# D1H.pdf register map
Vendor: Allwinner; Series: D1H.pdf; File version: 0.1
CPU: XuanTie C906 RISC-V CPU 0, little endian, MPU, FPU, double-precision FPU, 0 interrupt priority bits
Registers are 32-bit, read-write, reset 0x0 unless marked. A register's access mark holds for its fields unless they carry their own. Offsets are from the block's base; [hi:lo] are bit positions; {n}, {i} and the like mark numbered series; 'fields as' and 'values as' point back to an identical list; <NAME> marks a mode.

## SPI_DBI
Base 0x04026000
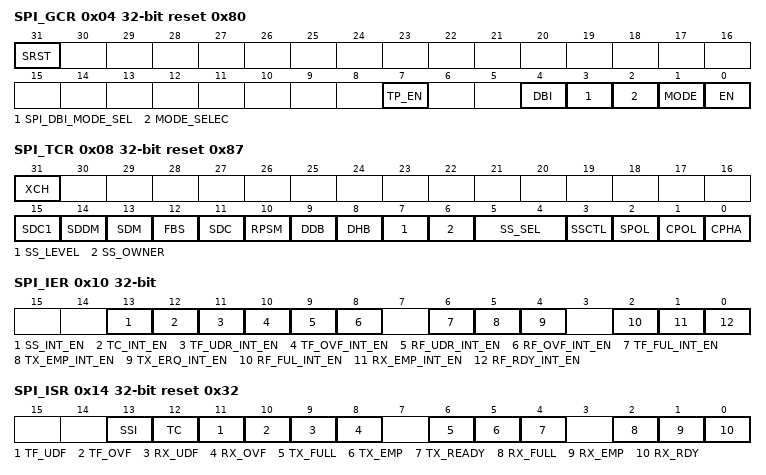
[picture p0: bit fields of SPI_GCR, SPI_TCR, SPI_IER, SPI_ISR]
0x04 SPI_GCR reset 0x80 — SPI Global Control Register
  [31] SRST — Soft reset Writing ‘1’ to this bit will clear the SPI controller, and auto clear to ‘0’ when reset operation completes. Writing ‘0’ to this bit has no effect.
  [7] TP_EN — Transmit Pause Enable In master mode, it is used to control transmit state machine to stop smart burst sending when RX FIFO is full. 0: Normal operation, ignore RXFIFO status 1: Stop transmit data when RXFIFO full Cannot be written when XCH=1.
    0=Normal operation, ignore RXFIFO status; 1=Stop transmit data when RXFIFO full Cannot be written when XCH=1
  [4] DBI — EN DBI Module Enable Control 0: Disable 1: Enable
    0=Disable; 1=Enable
  [3] SPI_DBI_MODE_SEL — DBI Working Mode Select 0: SPI MODE 1: DBI MODE
    0=SPI (SPI MODE); 1=DBI (DBI MODE)
  [2] MODE_SELEC — Sample Timing Mode Select 0: Old mode of Sample Timing 1: New mode of Sample Timing Cannot be written when XCH=1.
    0=Old mode of Sample Timing; 1=New mode of Sample Timing Cannot be written when XCH=1
  [1] MODE — SPI Function Mode Select 0: Slave mode 1: Master mode Cannot be written when XCH=1.
    0=Slave_mode; 1=Master mode Cannot be written when XCH=1
  [0] EN — SPI Module Enable Control 0: Disable 1: Enable After transforming from bit_mode to byte_mode, it must enable the SPI module again.
    0=Disable; 1=Enable After transforming from bit_mode to byte_mode, it must enable the SPI module again
0x08 SPI_TCR reset 0x87 — SPI Transfer Control Register
  [31] XCH — Exchange Burst In master mode, it is used to start SPI burst 0: Idle 1: Initiates exchange. Writing “1” to this bit will start the SPI burst, and will auto-clear after finishing the bursts transfer specified by BC. Writing “1” to SRST will also clear this bit. Writing ‘0’ to this bit has no effect. Cannot be written when XCH=1.
    0=Idle; 1=Initiates exchange. Writing “1” to this bit will start the SPI burst, and will auto-clear after finishing the bursts transfer specified by BC. Writing “1” to SRST will also clear this bit. Writing ‘0’ to this bit has no effect. Cannot be written when XCH=1.
  [15] SDC1 — Master Sample Data Control register1 Set this bit to ‘1’ to make the internal read sample point with a delay of half-cycle of SPI_CLK. It is used in high speed read operation to reduce the error caused by the time delay of SPI_CLK between master and slave. 0: Normal operation, do not delay the internal read sample point 1: Delay the internal read sample point Cannot be written when XCH=1.
    0=Normal operation, do not delay the internal read sample point; 1=Delay the internal read sample point Cannot be written when XCH=1
  [14] SDDM — Sending Data Delay Mode 0: Normal sending 1: Delay sending Set the bit to "1" to make the data that should be sent with a delay of half-cycle of SPI_CLK in dual IO mode for SPI mode 0. Cannot be written when XCH=1.
    0=Normal sending; 1=Delay sending Set the bit to "1" to make the data that should be sent with a delay of half-cycle of SPI_CLK in dual IO mode for SPI mode 0. Cannot be written when XCH=1.
  [13] SDM — Master Sample Data Mode 0: Delay sample mode 1: Normal sample mode In normal sample mode, the SPI master samples the data at the correct edge for each SPI mode; In delay sample mode, the SPI master samples data at the edge that is half cycle delayed by the correct edge defined in respective SPI mode. Cannot be written when XCH=1.
    0=Delay sample mode; 1=Normal sample mode In normal sample mode, the SPI master samples the data at the correct edge for each SPI mode; In delay sample mode, the SPI master samples data at the edge that is half cycle delayed by the correct edge defined in respective SPI mode. Cannot be written when XCH=1.
  [12] FBS — First Transmit Bit Select 0: MSB first. The upper bits are transmitted first. 1: LSB first. The lower bits are transmitted first. Cannot be written when XCH=1.
    0=MSB (MSB first. The upper bits are transmitted first.); 1=LSB (LSB first. The lower bits are transmitted first. Cannot be written when XCH=1.)
  [11] SDC — Master Sample Data Control Set this bit to ‘1’ to make the internal read sample point with a delay of half-cycle of SPI_CLK. It is used in high speed read operation to reduce the error caused by the time delay of SPI_CLK between master and slave. 0: Normal operation, do not delay the internal read sample point 1: Delay the internal read sample point Cannot be written when XCH=1.
    values as SDC1
  [10] RPSM — Rapids Mode Select Select rapid mode for high speed write. 0: Normal write mode 1: Rapid write mode Cannot be written when XCH=1.
    0=Normal write mode; 1=Rapid write mode Cannot be written when XCH=1
  [9] DDB — Dummy Burst Type 0: The bit value of dummy SPI burst is zero 1: The bit value of dummy SPI burst is one Cannot be written when XCH=1.
    0=zero (The bit value of dummy SPI burst is zero); 1=one (The bit value of dummy SPI burst is one Cannot be written when XCH=1.)
  [8] DHB — Discard Hash Burst In master mode, it controls whether discarding unused SPI bursts 0: Receiving all SPI bursts in the BC period 1: Discard unused SPI bursts, only fetching the SPI bursts during the dummy burst period. The burst number is specified by TC. Cannot be written when XCH=1.
    0=Receiving all SPI bursts in the BC period; 1=Discard unused SPI bursts, only fetching the SPI bursts during the dummy burst period. The burst number is specified by TC. Cannot be written when XCH=1.
  [7] SS_LEVEL — SPI Chip Select Level When control SS signal manually (SS_OWNER (SPI_TCR[6])==1), set this bit to ‘1’ or ‘0’ to control the level of SS signal. 0: Set SS to low 1: Set SS to high Cannot be written when XCH=1.
    0=Set_SS_to_low; 1=Set SS to high Cannot be written when XCH=1
  [6] SS_OWNER — SS Output Owner Select Usually, the controller sends the SS signal automatically with data together. When this bit is set to 1, the software must manually write SS_LEVEL (SPI_TCR[7]) to 1 or 0 to control the level of the SS signal. 0: SPI controller 1: Software Cannot be written when XCH=1.
    0=SPI (SPI controller); 1=Software Cannot be written when XCH=1
  [5:4] SS_SEL — SPI Chip Select Select one of four external SPI Master/Slave Devices 00: SPI_SS0 will be asserted 01: SPI_SS1 will be asserted 10: SPI_SS2 will be asserted 11: SPI_SS3 will be asserted Cannot be written when XCH=1.
    0=SPI_SS0 (SPI_SS0 will be asserted); 1=SPI_SS1 (SPI_SS1 will be asserted); 2=SPI_SS2 (SPI_SS2 will be asserted); 3=SPI_SS3 (SPI_SS3 will be asserted Cannot be written when XCH=1.)
  [3] SSCTL — In master mode, this bit selects the output waveform for the SPI_SSx signal. Only valid when SS_OWNER (SPI_TCR[6])= 0. 0: SPI_SSx remains asserted between SPI bursts 1: Negate SPI_SSx between SPI bursts Cannot be written when XCH=1.
    0=SPI_SSx remains asserted between SPI bursts; 1=Negate SPI_SSx between SPI bursts Cannot be written when XCH=1
  [2] SPOL — SPI Chip Select Signal Polarity Control 0: Active high polarity (0 = Idle) 1: Active low polarity (1 = Idle) Cannot be written when XCH=1.
    0=Active high polarity (0 = Idle); 1=Active low polarity (1 = Idle) Cannot be written when XCH=1
  [1] CPOL — SPI Clock Polarity Control 0: Active high polarity (0 = Idle) 1: Active low polarity (1 = Idle) Cannot be written when XCH=1.
    values as SPOL
  [0] CPHA — SPI Clock/Data Phase Control 0: Phase 0 (Leading edge for sample data) 1: Phase 1 (Leading edge for setup data) Cannot be written when XCH=1.
    0=Phase 0 (Leading edge for sample data); 1=Phase 1 (Leading edge for setup data) Cannot be written when XCH=1
0x10 SPI_IER — SPI Interrupt Control Register
  [all] fields
    0=Disable; 1=Enable
  [13] SS_INT_EN — SSI Interrupt Enable Chip select signal (SSx) from the valid state to the invalid state 0: Disable 1: Enable
  [12] TC_INT_EN — Transfer Completed Interrupt Enable 0: Disable 1: Enable
  [11] TF_UDR_INT_EN — TXFIFO Underrun Interrupt Enable 0: Disable 1: Enable
  [10] TF_OVF_INT_EN — TX FIFO Overflow Interrupt Enable 0: Disable 1: Enable
  [9] RF_UDR_INT_EN — RXFIFO Underrun Interrupt Enable 0: Disable 1: Enable
  [8] RF_OVF_INT_EN — RX FIFO Overflow Interrupt Enable 0: Disable 1: Enable
  [6] TF_FUL_INT_EN — TX FIFO Full Interrupt Enable 0: Disable 1: Enable
  [5] TX_EMP_INT_EN — TX FIFO Empty Interrupt Enable 0: Disable 1: Enable
  [4] TX_ERQ_INT_EN — TX FIFO Empty Request Interrupt Enable 0: Disable 1: Enable
  [2] RF_FUL_INT_EN — RX FIFO Full Interrupt Enable 0: Disable 1: Enable
  [1] RX_EMP_INT_EN — RX FIFO Empty Interrupt Enable 0: Disable 1: Enable
  [0] RF_RDY_INT_EN — RX FIFO Ready Request Interrupt Enable 0: Disable 1: Enable
0x14 SPI_ISR reset 0x32 — SPI Interrupt Status Register
  [13] SSI write-1-clears — SS Invalid Interrupt When SSI is 1, it indicates that SS has changed from the valid state to the invalid state. Writing 1 to this bit clears it.
  [12] TC write-1-clears — Transfer Completed In master mode, it indicates that all bursts specified by BC have been exchanged. In other conditions, when set, this bit indicates that all the data in TXFIFO has been loaded in the Shift register, and the Shift register has shifted out all the bits. Writing 1 to this bit clears it. 0: Busy 1: Transfer completed
    0=Busy; 1=Transfer completed
  [11] TF_UDF write-1-clears — TXFIFO Underrun This bit is set when the TXFIFO is underrun. Writing 1 to this bit clears it. 0: TXFIFO is not underrun 1: TXFIFO is underrun
    0=not_underrun (TXFIFO is not underrun); 1=underrun (TXFIFO is underrun)
  [10] TF_OVF write-1-clears — TXFIFO Overflow This bit is set when the TXFIFO is overflowed. Writing 1 to this bit clears it. 0: TXFIFO is not overflowed 1: TXFIFO is overflowed
    0=not_overflowed (TXFIFO is not overflowed); 1=overflowed (TXFIFO is overflowed)
  [9] RX_UDF write-1-clears — RXFIFO Underrun When set, this bit indicates that RXFIFO is underrun. Writing 1 to this bit clears it. 0: RXFIFO is not underrun 1: RXFIFO is underrun
    0=not_underrun (RXFIFO is not underrun); 1=underrun (RXFIFO is underrun)
  [8] RX_OVF write-1-clears — RXFIFO Overflow When set, this bit indicates that RXFIFO is overflowed. Writing 1 to this bit clears it. 0: RXFIFO is not overflowed 1: RXFIFO is overflowed
    0=not_overflowed (RXFIFO is not overflowed); 1=overflowed (RXFIFO is overflowed)
  [6] TX_FULL write-1-clears — TXFIFO Full This bit is set when the TXFIFO is full. Writing 1 to this bit clears it. 0: TXFIFO is not Full 1: TXFIFO is Full
    0=not_Full (TXFIFO is not Full); 1=Full (TXFIFO is Full)
  [5] TX_EMP write-1-clears — TXFIFO Empty This bit is set when the TXFIFO is empty. Writing 1 to this bit clears it. 0: TXFIFO contains one or more words. 1: TXFIFO is empty
    0=TXFIFO contains one or more words; 1=empty (TXFIFO is empty)
  [4] TX_READY write-1-clears — TXFIFO Ready 0: TX_WL > TX_TRIG_LEVEL 1: TX_WL <= TX_TRIG_LEVEL This bit will be immediately set to 1 if TX_WL <= TX_TRIG_LEVEL. Writing “1” to this bit clears it. The TX_WL is the water level of TXFIFO.
    0=TX_WL__gt_ (TX_WL > TX_TRIG_LEVEL); 1=TX_WL__lt__equals_ (TX_WL <= TX_TRIG_LEVEL This bit will be immediately set to 1 if TX_WL <= TX_TRIG_LEVEL. Writing “1” to this bit clears it. The TX_WL is the water level of TXFIFO.)
  [2] RX_FULL write-1-clears — RXFIFO Full This bit is set when the RXFIFO is full. Writing 1 to this bit clears it. 0: Not Full 1: Full
    0=Not_Full; 1=Full
  [1] RX_EMP write-1-clears — RXFIFO Empty This bit is set when the RXFIFO is empty. Writing 1 to this bit clears it. 0: Not empty 1: empty
    0=Not_empty; 1=empty
  [0] RX_RDY write-1-clears — RXFIFO Ready 0: RX_WL < RX_TRIG_LEVEL 1: RX_WL >= RX_TRIG_LEVEL This bit will be immediately set to 1 if RX_WL >= RX_TRIG_LEVEL. Writing “1” to this bit clears it. The RX_WL is the water level of RXFIFO.
    0=RX_WL__lt_ (RX_WL < RX_TRIG_LEVEL); 1=RX_WL__gt__equals_ (RX_WL >= RX_TRIG_LEVEL This bit will be immediately set to 1 if RX_WL >= RX_TRIG_LEVEL. Writing “1” to this bit clears it. The RX_WL is the water level of RXFIFO.)
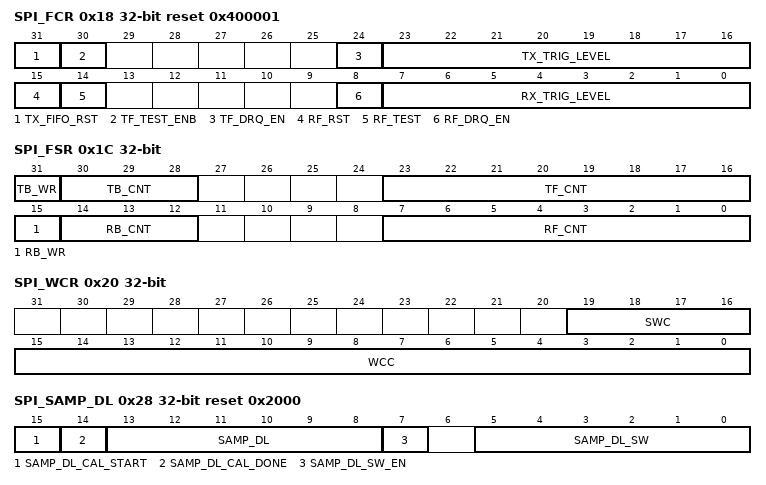
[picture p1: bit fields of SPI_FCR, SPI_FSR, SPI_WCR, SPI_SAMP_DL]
0x18 SPI_FCR reset 0x400001 — SPI FIFO Control Register
  [31] TX_FIFO_RST — TX FIFO Reset Writing ‘1’ to this bit will reset the control portion of the TXFIFO and auto clear to ‘0’ when completing the reset operation, writing ‘0’ to this bit has no effect.
  [30] TF_TEST_ENB — TX Test Mode Enable 0: Disable 1: Enable In normal mode, the TXFIFO can only be read by the SPI controller, writing ‘1’ to this bit will switch the read and write function of TXFIFO to AHB bus. This bit is used to test the TXFIFO, do not set in normal operation, and do not set RF_TEST and TF_TEST at the same time.
    0=Disable; 1=Enable In normal mode, the TXFIFO can only be read by the SPI controller, writing ‘1’ to this bit will switch the read and write function of TXFIFO to AHB bus. This bit is used to test the TXFIFO, do not set in normal operation, and do not set RF_TEST and TF_TEST at the same time.
  [24] TF_DRQ_EN — TX FIFO DMA Request Enable 0: Disable 1: Enable
    0=Disable; 1=Enable
  [23:16] TX_TRIG_LEVEL — TX FIFO Empty Request Trigger Level
  [15] RF_RST — RXFIFO Reset Writing ‘1’ to this bit will reset the control portion of the receiver FIFO, and auto clear to ‘0’ when completing the reset operation, writing ‘0’ to this bit has no effect.
  [14] RF_TEST — RX Test Mode Enable 0: Disable 1: Enable In normal mode, the RXFIFO can only be written by the SPI controller, writing ‘1’ to this bit will switch the read and write function of RXFIFO to AHB bus. This bit is used to test the RXFIFO, do not set in normal operation, and do not set RF_TEST and TF_TEST at the same time.
    0=Disable; 1=Enable In normal mode, the RXFIFO can only be written by the SPI controller, writing ‘1’ to this bit will switch the read and write function of RXFIFO to AHB bus. This bit is used to test the RXFIFO, do not set in normal operation, and do not set RF_TEST and TF_TEST at the same time.
  [8] RF_DRQ_EN — RXFIFO DMA Request Enable 0: Disable 1: Enable
    0=Disable; 1=Enable
  [7:0] RX_TRIG_LEVEL — RXFIFO Ready Request Trigger Level
0x1C SPI_FSR — SPI FIFO Status Register
  [31] TB_WR ro — TXFIFO Write Buffer Write Enable
  [30:28] TB_CNT ro — TXFIFO Write Buffer Counter These bits indicate the number of words in TXFIFO Write Buffer
  [23:16] TF_CNT ro — TXFIFO Counter These bits indicate the number of words in TXFIFO 0: 0 byte in TXFIFO 1: 1 byte in TXFIFO … 64: 64 bytes in TXFIFO other: Reserved
    64=64 bytes in TXFIFO other: Reserved
  [15] RB_WR ro — RXFIFO Read Buffer Write Enable
  [14:12] RB_CNT ro — RXFIFO Read Buffer Counter These bits indicate the number of words in RXFIFO Read Buffer
  [7:0] RF_CNT ro — RXFIFO Counter These bits indicate the number of words in RXFIFO 0: 0 byte in RXFIFO 1: 1 byte in RXFIFO … 64: 64 bytes in RXFIFO other: Reserved
    64=64 bytes in RXFIFO other: Reserved
0x20 SPI_WCR — SPI Wait Clock Register
  [19:16] SWC — Dual mode direction switch wait clock counter (for master mode only). These bits control the number of wait states to be inserted before starting dual data transfer in dual SPI mode. The SPI module counts SPI_SCLK by SWC for delaying the next word data transfer. 0: No wait states inserted n: n SPI_SCLK wait states inserted Cannot be written when XCH=1.
  [15:0] WCC — Wait Clock Counter (In master mode) These bits control the number of wait states to be inserted in data transfers. The SPI module counts SPI_SCLK by WCC for delaying the next word data transfer. 0: No wait states inserted n: n SPI_SCLK wait states inserted Cannot be written when XCH=1.
0x28 SPI_SAMP_DL reset 0x2000 — SPI Sample Delay Control Register
  [15] SAMP_DL_CAL_START — Sample Delay Calibration Start When set, it indicates that start sample delay chain calibration. Cannot be written when XCH=1.
  [14] SAMP_DL_CAL_DONE ro — Sample Delay Calibration Done When set, it indicates that the sample delay chain calibration is done and the result of calibration is shown in SAMP_DL. Cannot be written when XCH=1.
  [13:8] SAMP_DL ro — Sample Delay It indicates the number of delay cells corresponding to the current card clock. The delay time generated by these delay cells is equal to the cycle of the card clock nearly. Generally, it is necessary to do drive delay calibration when the card clock is changed. This bit is valid only when SAMP_DL_CAL_DONE is set. Cannot be written when XCH=1.
  [7] SAMP_DL_SW_EN — Sample Delay Software Enable When set, it indicates that enable sample delay specified at SAMP_DL_SW Cannot be written when XCH=1.
  [5:0] SAMP_DL_SW — Sample Delay Software The relative delay between the clock line and command line, data lines. It can be determined according to the value of SAMP_DL, the cycle of the card clock, and the input timing requirement of the device. Cannot be written when XCH=1.
0x30 SPI_MBC — SPI Master Burst Counter Register
  [23:0] MBC — Master Burst Counter In master mode, this field specifies the total burst number which includes the TXD, RXD, and dummy burst. 0: 0 burst 1: 1 burst … N: N bursts Cannot be written when XCH=1.
0x34 SPI_MTC — SPI Master Transmit Counter Register
  [23:0] MWTC — Master Write Transmit Counter In master mode, this field specifies the burst number that should be sent to TXFIFO before automatically sending dummy bursts. For saving bus bandwidth, the dummy bursts (all zero bits or all one bits) are sent by SPI Controller automatically. 0: 0 burst 1: 1 burst … N: N bursts Cannot be written when XCH=1.
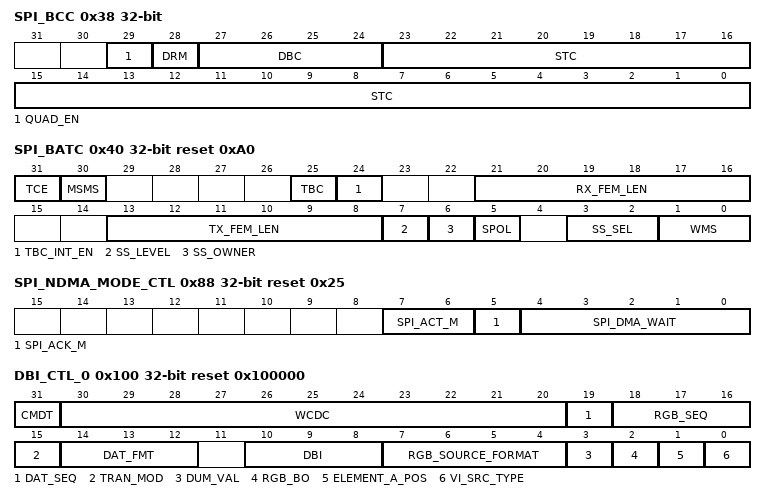
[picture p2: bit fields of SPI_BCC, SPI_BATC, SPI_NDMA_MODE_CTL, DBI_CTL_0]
0x38 SPI_BCC — SPI Master Burst Control Register
  [29] QUAD_EN — Quad_Mode_EN The Quad mode includes Quad-Input and Quad-Output. 0: Quad mode disable 1: Quad mode enable Cannot be written when XCH=1.
    0=disable (Quad mode disable); 1=enable (Quad mode enable Cannot be written when XCH=1.)
  [28] DRM — Master Dual Mode RX Enable It is only valid when Quad_Mode_EN=0. 0: RX uses the single-bit mode 1: RX uses the dual mode Cannot be written when XCH=1.
    0=RX uses the single-bit mode; 1=RX uses the dual mode Cannot be written when XCH=1
  [27:24] DBC — Master Dummy Burst Counter In master mode, this field specifies the burst number that should be sent before receiving in dual SPI mode. The data does not care by the device. 0: 0 burst 1: 1 burst … N: N bursts Cannot be written when XCH=1
  [23:0] STC — Master Single Mode Transmit Counter In master mode, this field specifies the burst number that should be sent in the single mode before automatically sending dummy bursts. This is the first transmit counter in all bursts. 0: 0 burst 1: 1 burst … N: N bursts Cannot be written when XCH=1
0x40 SPI_BATC reset 0xA0
  [31] TCE — Transfer Control Enable In master mode, it is used to start to transfer the serial bits frame, it is only valid when Work Mode Select==0x10/0x11. 0: Idle 1: Initiates transfer Writing “1” to this bit will start to transfer serial bits frame (the value comes from the SPI TX Bit Register or SPI RX Bit Register), and will auto-clear after the bursts transfer completely. Writing ‘0’ to this bit has no effect.
    0=Idle; 1=Initiates transfer Writing “1” to this bit will start to transfer serial bits frame (the value comes from the SPI TX Bit Register or SPI RX Bit Register), and will auto-clear after the bursts transfer completely. Writing ‘0’ to this bit has no effect.
  [30] MSMS — Master Sample Standard 0: Delay Sample Mode 1: Standard Sample Mode In Standard Sample Mode, the SPI master samples the data at the standard rising edge of SCLK for each SPI mode; In Delay Sample Mode, the SPI master samples data at the edge that is half cycle delayed by the standard rising edge of SCLK defined in respective SPI mode.
    0=Delay Sample Mode; 1=Standard Sample Mode In Standard Sample Mode, the SPI master samples the data at the standard rising edge of SCLK for each SPI mode; In Delay Sample Mode, the SPI master samples data at the edge that is half cycle delayed by the standard rising edge of SCLK defined in respective SPI mode
  [25] TBC write-1-clears — Transfer Bits Completed When set, this bit indicates that the last bit of the serial data frame in SPI TX Bit Register (or SPI RX Bit Register) has been transferred completely. Writing 1 to this bit clears it. 0: Busy 1: Transfer Completed It is only valid when Work Mode Select==0x10/0x11.
    0=Busy; 1=Transfer Completed It is only valid when Work Mode Select==0x10/0x11
  [24] TBC_INT_EN — Transfer Bits Completed Interrupt Enable 0: Disable 1: Enable It is only valid when Work Mode Select==0x10/0x11.
    0=Disable; 1=Enable It is only valid when Work Mode Select==0x10/0x11
  [21:16] RX_FEM_LEN — Configure the length of serial data frame (burst) of RX 000000: 0 bit 000001: 1 bit … 100000: 32 bits Other values: reserved It is only valid when Work Mode Select==0x10/0x11, and cannot be written when TCE (SPI_BATC[31])=1.
    0=_0_bit; 1=_1_bit; 32=32 bits Other values: reserved It is only valid when Work Mode Select==0x10/0x11, and cannot be written when TCE (SPI_BATC[31])=1
  [13:8] TX_FEM_LEN — Configure the length of serial data frame (burst) of TX 000000: 0 bit 000001: 1 bit … 100000: 32 bits Other values: reserved It is only valid when Work Mode Select==0x10/0x11, and cannot be written when TCE=1.
    0=_0_bit; 1=_1_bit; 32=32 bits Other values: reserved It is only valid when Work Mode Select==0x10/0x11, and cannot be written when TCE=1
  [7] SS_LEVEL — When control SS signal manually, set this bit to ‘1’ or ‘0’ to control the level of SS signal. 0: Set SS to low 1: Set SS to high It is only valid when Work Mode Select==0x10/0x11, and only work in Mode0, cannot be written when TCE=1.
    0=Set_SS_to_low; 1=Set SS to high It is only valid when Work Mode Select==0x10/0x11, and only work in Mode0, cannot be written when TCE=1
  [6] SS_OWNER — SS Output Owner Select Usually, the controller sends the SS signal automatically with data together. When this bit is set to 1, the software must manually write SS_LEVEL (SPI_BATC[7]) to 1 or 0 to control the level of the SS signal. 0: SPI controller 1: Software It is only valid when Work Mode Select==0x10/0x11, and only work in Mode0, cannot be written when TCE=1.
    0=SPI (SPI controller); 1=Software It is only valid when Work Mode Select==0x10/0x11, and only work in Mode0, cannot be written when TCE=1
  [5] SPOL — SPI Chip Select Signal Polarity Control 0: Active high polarity (0 = Idle) 1: Active low polarity (1 = Idle) It is only valid when Work Mode Select==0x10/0x11, and only work in Mode0, cannot be written when TCE=1.
    0=Active high polarity (0 = Idle); 1=Active low polarity (1 = Idle) It is only valid when Work Mode Select==0x10/0x11, and only work in Mode0, cannot be written when TCE=1
  [3:2] SS_SEL — SPI Chip Select Select one of four external SPI Master/Slave Devices 00: SPI_SS0 will be asserted 01: SPI_SS1 will be asserted 10: SPI_SS2 will be asserted 11: SPI_SS3 will be asserted It is only valid when Work Mode Select==0x10/0x11, and only work in Mode0, cannot be written when TCE=1.
    0=SPI_SS0 (SPI_SS0 will be asserted); 1=SPI_SS1 (SPI_SS1 will be asserted); 2=SPI_SS2 (SPI_SS2 will be asserted); 3=SPI_SS3 (SPI_SS3 will be asserted It is only valid when Work Mode Select==0x10/0x11, and only work in Mode0, cannot be written when TCE=1.)
  [1:0] WMS — Work Mode Select 00: Data frame is byte aligned in standard SPI, dual-output/dual input SPI, dual IO SPI, and quad-output/quad-input SPI 01: Reserved 10: Data frame is bit aligned in 3-wire SPI 11: Data frame is bit aligned in standard SPI
    0=byte_aligned_in_standard (Data frame is byte aligned in standard SPI, dual-output/dual input SPI, dual IO SPI, and quad-output/quad-input SPI); 2=bit_aligned_in_3_wire (Data frame is bit aligned in 3-wire SPI); 3=bit_aligned_in_standard (Data frame is bit aligned in standard SPI)
0x44 SPI_BA_CCR — SPI Bit-Aligned Clock Configuration Register
  [7:0] CDR_N — Clock Divide Rate (Master Mode Only) The SPI_SCLK is determined according to the following equation: SPI_CLK = Source_CLK / (2*(CDR_N + 1)). This register is only valid when Work Mode Select==0x10/0x11.
0x48 SPI_TBR — SPI TX Bit Register
  [31:0] VTB — The Value of the Transmit Bits This register is used to store the value of the transmitted serial data frame. In the process of transmission, the LSB is transmitted first. This register is only valid when Work Mode Select==0x10/0x11.
0x4C SPI_RBR — SPI RX Bit Register
  [31:0] VRB — The Value of the Receive Bits This register is used to store the value of the received serial data frame. In the process of transmission, the LSB is transmitted first. This register is only valid when Work Mode Select==0x10/0x11.
0x88 SPI_NDMA_MODE_CTL reset 0x25 (reset mask 0x3F) — SPI Normal DMA Mode Control Register
  [7:6] SPI_ACT_M — SPI NDMA Active Mode 00: dma_active is low 01: dma_active is high 10: dma_active is controlled by dma_request (DRQ) 11: dma_active is controlled by controller
  [5] SPI_ACK_M — SPI NDMA Acknowledge Mode 0: active fall do not care ack 1: active fall must after detect ack is high
    0=active fall do not care ack; 1=active fall must after detect ack is high
  [4:0] SPI_DMA_WAIT — Delay Cycles The counts of hold cycles from DMA last signal high to dma_active high
0x100 DBI_CTL_0 reset 0x100000 — DBI Control Register 0
  [31] CMDT — Command Type 0: Write Command 1: Read Command
    0=Write Command; 1=Read Command
  [30:20] WCDC — Write Command Dummy Cycles Controls dummy cycles between two write commands Range 1~255 Default Condition: there is a dbi_clk cycle between each command or parameter.
  [19] DAT_SEQ — Output Data Sequence 0: MSB First 1: LSB First
    0=MSB (MSB First); 1=LSB (LSB First)
  [18:16] RGB_SEQ — Output RGB Sequence 000: RGB 001: RBG 010: GRB 011: GBR 100: BRG 101: BGR 110, 111: Reserved
    0=RGB; 1=RBG; 2=GRB; 3=GBR; 4=BRG; 5=BGR (BGR 110, 111: Reserved)
  [15] TRAN_MOD — Transmit Mode 0: Command/Parameter 1: Video
    0=Command_slash_Parameter (Command/Parameter); 1=Video
  [14:12] DAT_FMT — Output Data Format 000: RGB111 001: RGB444 010: RGB565 011: RGB666 100: RGB888 (only for 2 Data Lane Interface) 101~111: Reserved
    0=RGB111; 1=RGB444; 2=RGB565; 3=RGB666; 4=RGB888 (RGB888 (only for 2 Data Lane Interface) 101~111: Reserved)
  [10:8] DBI — Interface 000: 3 Line Interface I 001: 3 Line Interface II 010: 4 Line Interface I 011: 4 Line Interface II 100: 2 Data Lane Interface
    0=_3_Line_Interface_I; 1=_3_Line_Interface_II; 2=_4_Line_Interface_I; 3=_4_Line_Interface_II; 4=_2_Data_Lane_Interface
  [7:4] RGB_SOURCE_FORMAT — When video_source_type is RGB32 (DBI_CTL_0[bit0] = 0) 0000: RGB 0001: RBG 0010: GRB 0011: GBR 0100: BRG 0101: BGR Others: Reserved When video_source_type is RGB16 (DBI_CTL_0[bit0] = 1) 0000: RGB 0001~0100: Reserved 0101: BGR 0110: GRBG_0 {G[5:3]R[4:0]B[4:0]G[2:0]} 0111: GBRG_0 {G[5:3]B[4:0]R[4:0]G[2:0]} 1000: GRBG_1 {G[2:0]R[4:0]B[4:0]G[5:3]} 1001: GBRG_1 {G[2:0]B[4:0]R[4:0]G[5:3]} Others: Reserved
  [3] DUM_VAL — Dummy Cycle Value Output Value During Dummy Cycle
  [2] RGB_BO — RGB Bit Order 0: Remain the sequence of RGB data 1: Swap the higher bit and the lower bit for each component of DRAM RGB
    0=Remain the sequence of RGB data; 1=Swap the higher bit and the lower bit for each component of DRAM RGB
  [1] ELEMENT_A_POS — Element A Position Only for RGB32 Data Format 0: A component is in the bit[31:24] of data source 1: A component is in the bit[7:0] of data source
    0=in_the_bit[31_colon_24] (A component is in the bit[31:24] of data source); 1=in_the_bit[7_colon_0] (A component is in the bit[7:0] of data source)
  [0] VI_SRC_TYPE — Video Source Type 0: RGB32 1: RGB16
    0=RGB32; 1=RGB16
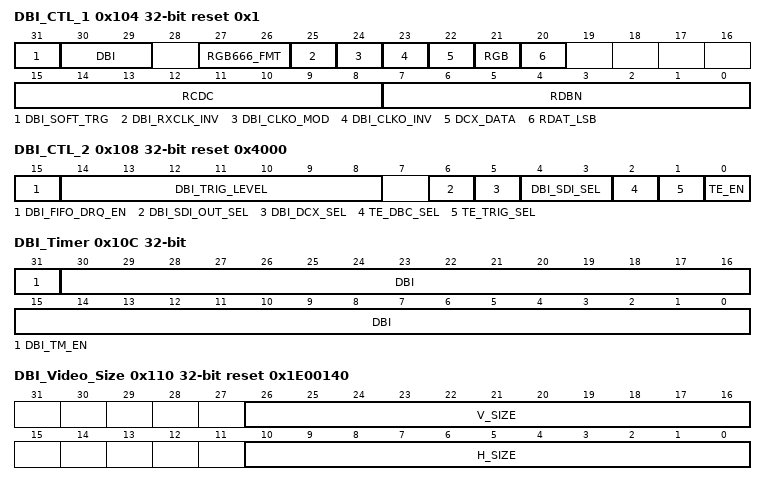
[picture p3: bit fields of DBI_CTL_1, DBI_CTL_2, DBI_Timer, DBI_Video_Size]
0x104 DBI_CTL_1 reset 0x1 — DBI Control Register 1
  [31] DBI_SOFT_TRG — DBI soft trigger It is only available for software trigger mode. Writing ‘1’ to this bit will start DBI TX module and auto clear to ‘0’ when completing start operation, writing ‘0’ to this bit has no effect.
  [30:29] DBI — EN MODE SEL DBI Enable Mode Select 00: Always on DBI mode 01: Software trigger mode 10: Timer trigger mode 11: TE trigger mode
    0=Always on DBI mode; 1=Software trigger mode; 2=Timer trigger mode; 3=TE (TE trigger mode)
  [27:26] RGB666_FMT — 2 Data Lane RGB666 Format 00: Normal Format 01: Special Format for ILITEK 10: Special Format for New Vision
  [25] DBI_RXCLK_INV — DBI rx clock inverse 0: Sample data by using the positive edge of the output clock 1: Sample data by using the negative edge of the output clock
    0=Sample data by using the positive edge of the output clock; 1=Sample data by using the negative edge of the output clock
  [24] DBI_CLKO_MOD — DBI output clock mode 0: DBI clock always on (DCX Setup/hold equals one clock cycle) 1: DBI clock auto gating (DCX Setup/hold equals to a half clock cycle)
    0=DBI clock always on (DCX Setup/hold equals one clock cycle); 1=DBI clock auto gating (DCX Setup/hold equals to a half clock cycle)
  [23] DBI_CLKO_INV — DBI clock output inverse 0: The falling edge releases the CSX signal, and the falling edge releases data 1: The rising edge releases the CSX signal, and the rising edge releases data 0: The rising edge releases the CSX signal, and the falling edge releases data 1: The falling edge releases the CSX signal, and the rising edge releases data
    0=falling_edge_releases_the_CSX_signal_comma__and_the_falling (The falling edge releases the CSX signal, and the falling edge releases data); 1=rising_edge_releases_the_CSX_signal_comma__and_the_rising (The rising edge releases the CSX signal, and the rising edge releases data); 0=rising_edge_releases_the_CSX_signal_comma__and_the_falling (The rising edge releases the CSX signal, and the falling edge releases data); 1=falling_edge_releases_the_CSX_signal_comma__and_the_rising (The falling edge releases the CSX signal, and the rising edge releases data)
  [22] DCX_DATA — DCX Data Value 0: DCX Value equal to 0 1: DCX Value equal to 1
    0=DCX_Value_equal_to_0; 1=DCX_Value_equal_to_1
  [21] RGB — 16 Data Source Select RGB 16 Data Source Select 0: Pixel1 is stored in the higher bit of address, and Pixel0 is stored in the lower bit of address 1: Pixel0 is stored in the higher bit of address, and Pixel1 is stored in the lower bit of address
    0=Pixel1 is stored in the higher bit of address, and Pixel0 is stored in the lower bit of address; 1=Pixel0 is stored in the higher bit of address, and Pixel1 is stored in the lower bit of address
  [20] RDAT_LSB — Bit Order of Read Data 0: A reading data is the higher bit 1: A reading data is the lower bit
    0=the_higher (A reading data is the higher bit); 1=the_lower (A reading data is the lower bit)
  [15:8] RCDC — Read Command Dummy Cycles The dummy cycle between the read command and read data Reading 1-byte (8 bits) data has not dummy cycle.
  [7:0] RDBN — Read Data Number of Bytes Sample Bytes data based on configuration.
0x108 DBI_CTL_2 reset 0x4000 — DBI Control Register 2
  [15] DBI_FIFO_DRQ_EN — DBI FIFO DMA Request Enable 0: Disable 1: Enable
    0=Disable; 1=Enable
  [14:8] DBI_TRIG_LEVEL — DBI FIFO Empty Request Trigger Level
  [6] DBI_SDI_OUT_SEL — DBI SDI PIN Output Select The signal is used with the DBI SDI PIN Function Sel bit. 0: Output WRX (When DBI DCX PIN Function Sel = 0, the SDI pin outputs data) 1: Output DCX
    0=Output WRX (When DBI DCX PIN Function Sel = 0, the SDI pin outputs data); 1=Output_DCX
  [5] DBI_DCX_SEL — DBI DCX PIN Function Select 0: DBI DCX Function 1: WRX (2 Data Lane Interface)
    0=DBI (DBI DCX Function); 1=WRX (WRX (2 Data Lane Interface))
  [4:3] DBI_SDI_SEL — DBI SDI PIN Function Select 00: DBI_SDI (Interface II) 01: DBI_TE 10: DBI_DCX 11: Reserved
    0=DBI_SDI (DBI_SDI (Interface II)); 1=DBI_TE; 2=DBI_DCX
  [2] TE_DBC_SEL — TE debounce function select 0: debounce 1: no-debounce
    0=debounce; 1=no_debounce
  [1] TE_TRIG_SEL — TE edge trigger select 0: TE rising edge 1: TE falling edge
    0=TE_rising_edge; 1=TE_falling_edge
  [0] TE_EN — TE enable 0: TE Disable 1: TE Enable
    0=TE_Disable; 1=TE_Enable
0x10C DBI_Timer
  [31] DBI_TM_EN — DBI Timer Enable 0: Enable 1: Disable
    0=Enable; 1=Disable
  [30:0] DBI — Timer Value It sets the time interval between sending data twice, which is frame blanking. It is used to set the time at which the interrupt of the DBI Timer is triggered. When the Timer_EN is 1, the timer starts to count (the clock of the counting is SCLK), and the counter reaches the target value to trigger the Timer_INT of DBI, the data will start to send in series.
0x110 DBI_Video_Size reset 0x1E00140
  [26:16] V_SIZE — It is used to generate the Frame int.
  [10:0] H_SIZE — It is used to generate the Line int.
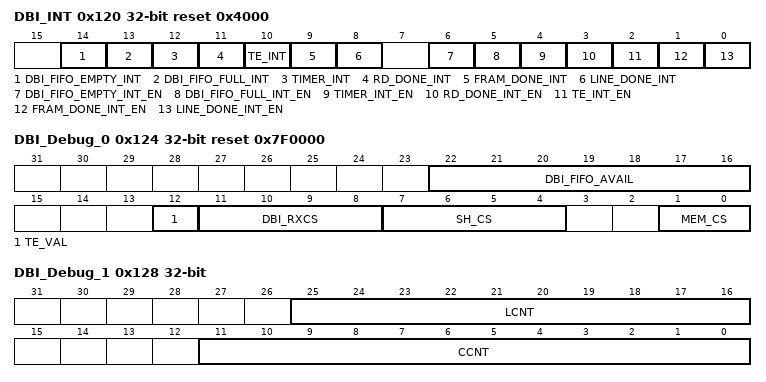
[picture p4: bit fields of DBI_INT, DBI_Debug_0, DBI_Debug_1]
0x120 DBI_INT reset 0x4000 — DBI Interrupt Register
  [14] DBI_FIFO_EMPTY_INT write-1-clears — DBI FIFO Empty Interrupt Status 0: DBI_FIFO is not empty 1: DBI_FIFO is empty
    0=not_empty (DBI_FIFO is not empty); 1=empty (DBI_FIFO is empty)
  [13] DBI_FIFO_FULL_INT write-1-clears — DBI FIFO Full Interrupt Status 0: DBI_FIFO is not full 1: DBI_FIFO is full
    0=not_full (DBI_FIFO is not full); 1=full (DBI_FIFO is full)
  [12] TIMER_INT write-1-clears — It indicates that the timer has been count sclk cycles to the value of DBI_Timer Register[30:0]. Writing 1 to this bit clears it. 0: Timer has not been achieved the objective 1: Timer has been achieved the objective
    0=Timer has not been achieved the objective; 1=Timer has been achieved the objective
  [11] RD_DONE_INT write-1-clears — It indicates that the number of byte setting in DBI_Control Register 1[19:8] has been read. Writing 1 to this bit clears it. 0: All data has not been read 1: All data has been read
    0=All data has not been read; 1=All data has been read
  [10] TE_INT write-1-clears — It indicates that the TE signal has been changed. Writing 1 to this bit clears it. 0: TE signal has not been changed 1: TE signal has been changed
    0=TE signal has not been changed; 1=TE signal has been changed
  [9] FRAM_DONE_INT write-1-clears — It indicates that a frame video data has been sent. Writing 1 to this bit clears it. 0: A frame video has not been sent 1: A frame video has been sent
    0=A frame video has not been sent; 1=A frame video has been sent
  [8] LINE_DONE_INT write-1-clears — It indicates that a line of video data has been sent. Writing 1 to this bit clears it. 0: A line of video data has not been sent 1: A line of video data has been sent
    0=A line of video data has not been sent; 1=A line of video data has been sent
  [6] DBI_FIFO_EMPTY_INT_EN — DBI FIFO Empty Interrupt Enable 0: Disable 1: Enable
    0=Disable; 1=Enable
  [5] DBI_FIFO_FULL_INT_EN — DBI FIFO Full Interrupt Enable 0: Disable 1: Enable
    0=Disable; 1=Enable
  [4] TIMER_INT_EN — Timer Interrupt Enable 0: Disable 1: Enable
    0=Disable; 1=Enable
  [3] RD_DONE_INT_EN — Read Done Interrupt Enable 0: Disable 1: Enable
    0=Disable; 1=Enable
  [2] TE_INT_EN — TE Interrupt Enable 0: Disable 1: Enable
    0=Disable; 1=Enable
  [1] FRAM_DONE_INT_EN — Frame Done Interrupt Enable 0: Disable 1: Enable
    0=Disable; 1=Enable
  [0] LINE_DONE_INT_EN — Line Done Interrupt Enable 0: Disable 1: Enable
    0=Disable; 1=Enable
0x124 DBI_Debug_0 reset 0x7F0000
  [22:16] DBI_FIFO_AVAIL ro — DBI_FIFO ROOM VALID 0~127 Words
  [12] TE_VAL ro — TE input value 0: TE not Trigger 1: TE Trigger
    0=TE_not_Trigger; 1=TE_Trigger
  [11:8] DBI_RXCS ro — FSM for DBI Receive RX_BS0 ~ RX_BS6 , Gray - Code
  [7:4] SH_CS ro — FSM for shifter 0~11 : SH0~SH11
  [1:0] MEM_CS ro — FSM for DBI Memory 00: IDLE_FRM 01: FRM_POS 10: FRM_RDY
    0=IDLE_FRM; 1=FRM_POS; 2=FRM_RDY
0x128 DBI_Debug_1
  [25:16] LCNT ro — Line counter The number of pixel lines that are currently sent
  [11:0] CCNT ro — Component counter The number of RGB components that are currently sent The field is equal to pixel_cnt *3.
0x200 SPI_TXD — SPI TX Data register
  [31:0] TDATA — Transmit Data This register can be accessed in the byte, half-word, or word unit by AHB. In the byte accessing method, if there are rooms in TXFIFO, one burst data is written to TXFIFO and the depth is increased by 1. In the half-word accessing method, two SPI burst data are written and the TXFIFO depth is increased by 2. In the word accessing method, four SPI burst data are written and the TXFIFO depth is increased by 4.
0x300 SPI_RXD — SPI RX Data register
  [31:0] RDATA ro — Receive Data This register can be accessed in the byte, half-word, or word unit by AHB. In the byte accessing method, if there are data in RXFIFO, the top word is returned and the RXFIFO depth is decreased by 1. In the half-word accessing method, two SPI bursts are returned and the RXFIFO depth is decreased by 2. In the word accessing method, the four SPI bursts are returned and the RXFIFO depth is decreased by 4.
